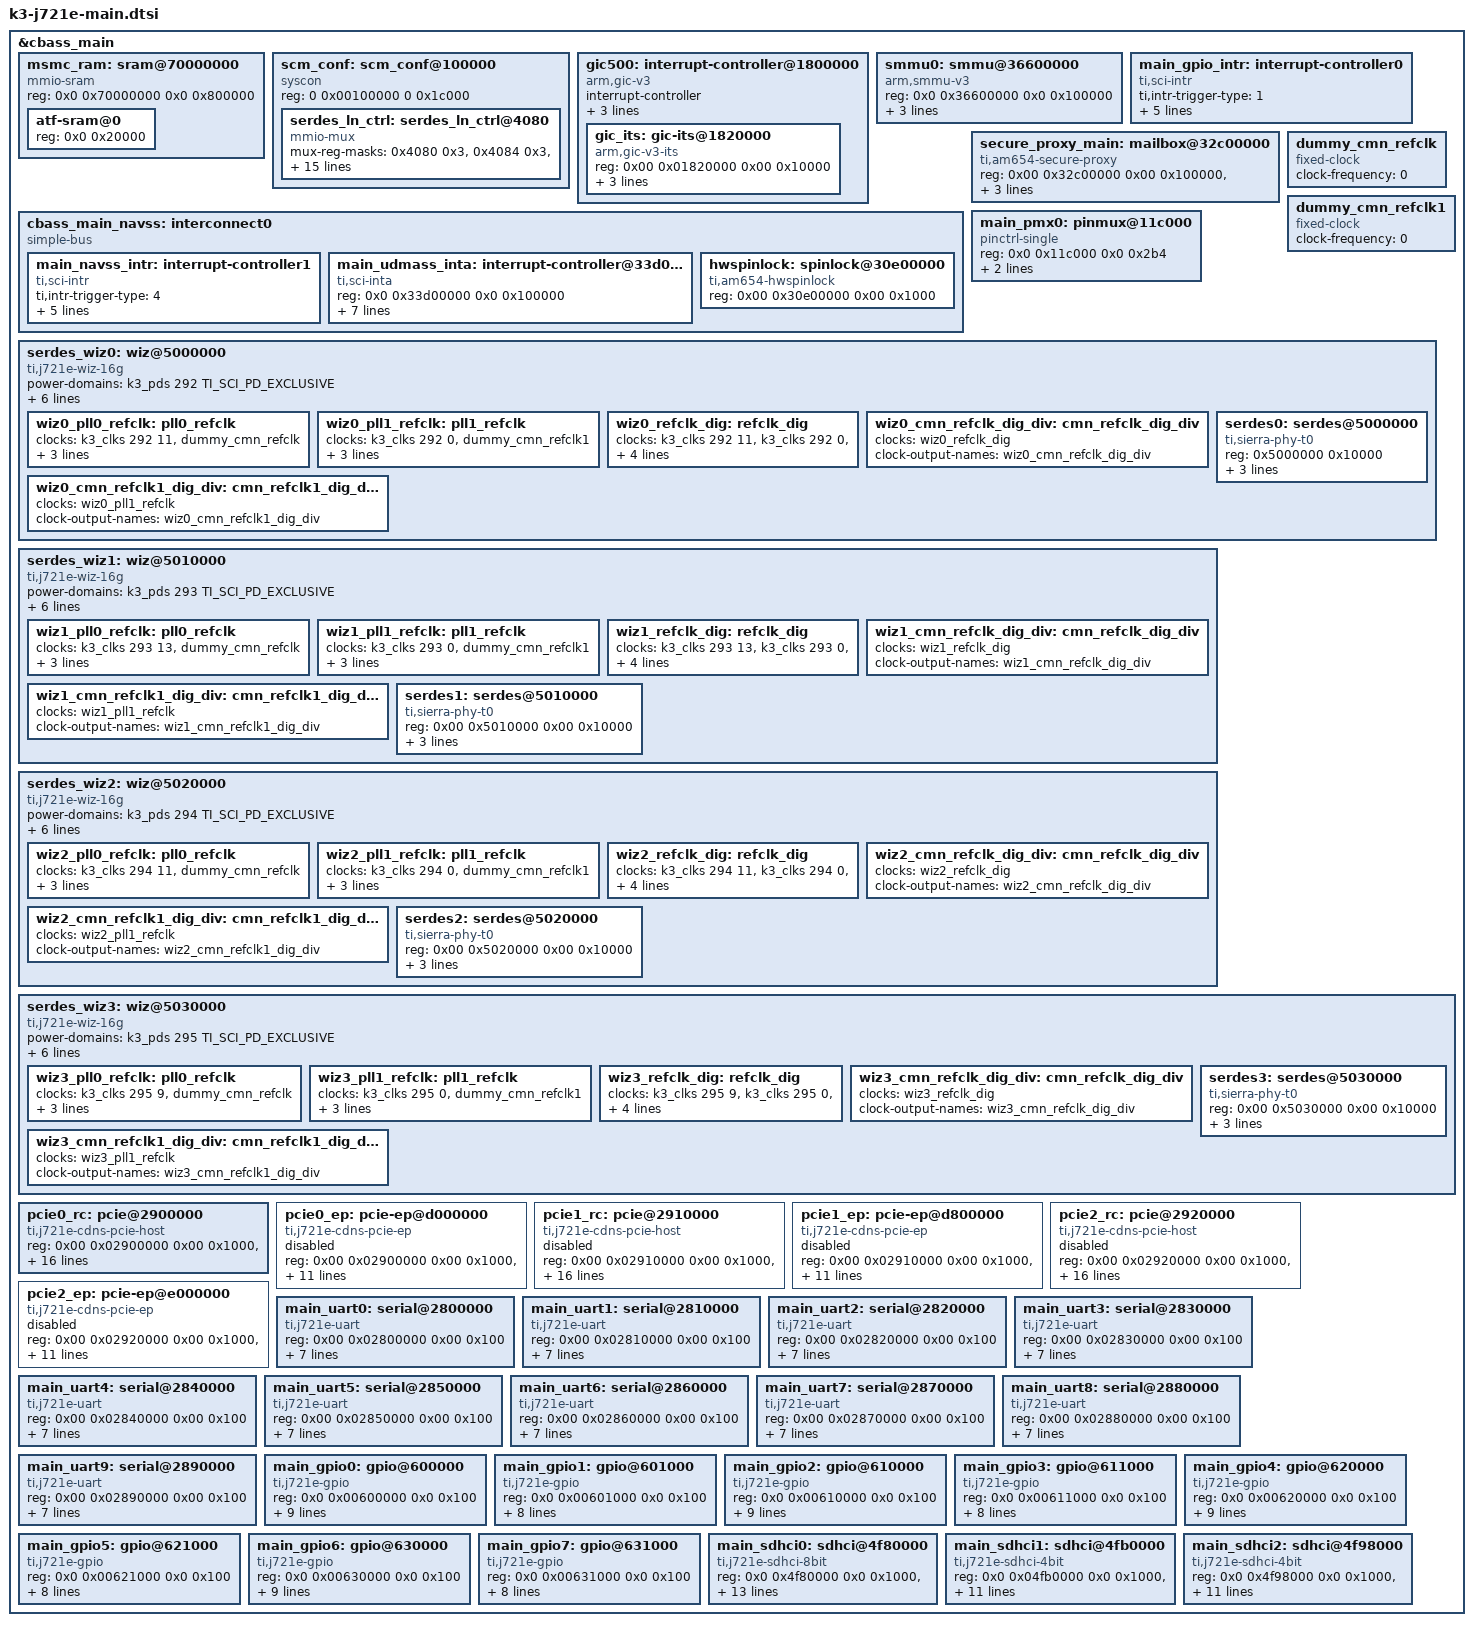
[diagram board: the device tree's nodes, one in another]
// SPDX-License-Identifier: GPL-2.0
/*
 * Device Tree Source for J721E SoC Family Main Domain peripherals
 *
 * Copyright (C) 2016-2019 Texas Instruments Incorporated - http://www.ti.com/
 */
#include <dt-bindings/phy/phy.h>
#include <dt-bindings/mux/mux.h>
#include <dt-bindings/mux/mux-j721e-wiz.h>

&cbass_main {
	msmc_ram: sram@70000000 {
		compatible = "mmio-sram";
		reg = <0x0 0x70000000 0x0 0x800000>;
		#address-cells = <1>;
		#size-cells = <1>;
		ranges = <0x0 0x0 0x70000000 0x800000>;

		atf-sram@0 {
			reg = <0x0 0x20000>;
		};
	};

	scm_conf: scm_conf@100000 {
		compatible = "syscon", "simple-mfd";
		reg = <0 0x00100000 0 0x1c000>;
		#address-cells = <1>;
		#size-cells = <1>;
		ranges = <0x0 0x0 0x00100000 0x1c000>;

		serdes_ln_ctrl: serdes_ln_ctrl@4080 {
			compatible = "mmio-mux";
			#mux-control-cells = <1>;
			mux-reg-masks = <0x4080 0x3>, <0x4084 0x3>, /* SERDES0 lane0/1 select */
					<0x4090 0x3>, <0x4094 0x3>, /* SERDES1 lane0/1 select */
					<0x40a0 0x3>, <0x40a4 0x3>, /* SERDES2 lane0/1 select */
					<0x40b0 0x3>, <0x40b4 0x3>, /* SERDES3 lane0/1 select */
					<0x40c0 0x3>, <0x40c4 0x3>, <0x40c8 0x3>, <0x40cc 0x3>;
					/* SERDES4 lane0/1/2/3 select */
			idle-states = <SERDES0_LANE0_PCIE0_LANE0>, <SERDES0_LANE1_PCIE0_LANE1>,
				      <SERDES1_LANE0_PCIE1_LANE0>, <SERDES1_LANE1_PCIE1_LANE1>,
				      <SERDES2_LANE0_PCIE2_LANE0>, <SERDES2_LANE1_PCIE2_LANE1>,
				      <MUX_IDLE_AS_IS>, <SERDES3_LANE1_USB3_0>,
				      <SERDES4_LANE0_EDP_LANE0>, <SERDES4_LANE1_EDP_LANE1>, <SERDES4_LANE2_EDP_LANE2>, <SERDES4_LANE3_EDP_LANE3>;
		};
	};

	gic500: interrupt-controller@1800000 {
		compatible = "arm,gic-v3";
		#address-cells = <2>;
		#size-cells = <2>;
		ranges;
		#interrupt-cells = <3>;
		interrupt-controller;
		reg = <0x00 0x01800000 0x00 0x10000>,	/* GICD */
		      <0x00 0x01900000 0x00 0x100000>;	/* GICR */

		/* vcpumntirq: virtual CPU interface maintenance interrupt */
		interrupts = <GIC_PPI 9 IRQ_TYPE_LEVEL_HIGH>;

		gic_its: gic-its@1820000 {
			compatible = "arm,gic-v3-its";
			reg = <0x00 0x01820000 0x00 0x10000>;
			socionext,synquacer-pre-its = <0x1000000 0x400000>;
			msi-controller;
			#msi-cells = <1>;
		};
	};

	smmu0: smmu@36600000 {
		compatible = "arm,smmu-v3";
		reg = <0x0 0x36600000 0x0 0x100000>;
		interrupt-parent = <&gic500>;
		interrupts = <GIC_SPI 772 IRQ_TYPE_EDGE_RISING>,
			     <GIC_SPI 768 IRQ_TYPE_EDGE_RISING>;
		interrupt-names = "eventq", "gerror";
		#iommu-cells = <1>;
	};

	main_gpio_intr: interrupt-controller0 {
		compatible = "ti,sci-intr";
		ti,intr-trigger-type = <1>;
		interrupt-controller;
		interrupt-parent = <&gic500>;
		#interrupt-cells = <2>;
		ti,sci = <&dmsc>;
		ti,sci-dst-id = <14>;
		ti,sci-rm-range-girq = <0x1>;
	};

	cbass_main_navss: interconnect0 {
		compatible = "simple-bus";
		#address-cells = <2>;
		#size-cells = <2>;
		ranges;

		main_navss_intr: interrupt-controller1 {
			compatible = "ti,sci-intr";
			ti,intr-trigger-type = <4>;
			interrupt-controller;
			interrupt-parent = <&gic500>;
			#interrupt-cells = <2>;
			ti,sci = <&dmsc>;
			ti,sci-dst-id = <14>;
			ti,sci-rm-range-girq = <0>, <2>;
		};

		main_udmass_inta: interrupt-controller@33d00000 {
			compatible = "ti,sci-inta";
			reg = <0x0 0x33d00000 0x0 0x100000>;
			interrupt-controller;
			interrupt-parent = <&main_navss_intr>;
			msi-controller;
			ti,sci = <&dmsc>;
			ti,sci-dev-id = <209>;
			ti,sci-rm-range-vint = <0xa>;
			ti,sci-rm-range-global-event = <0xd>;
		};

		hwspinlock: spinlock@30e00000 {
			compatible = "ti,am654-hwspinlock";
			reg = <0x00 0x30e00000 0x00 0x1000>;
			#hwlock-cells = <1>;
		};
	};

	secure_proxy_main: mailbox@32c00000 {
		compatible = "ti,am654-secure-proxy";
		#mbox-cells = <1>;
		reg-names = "target_data", "rt", "scfg";
		reg = <0x00 0x32c00000 0x00 0x100000>,
		      <0x00 0x32400000 0x00 0x100000>,
		      <0x00 0x32800000 0x00 0x100000>;
		interrupt-names = "rx_011";
		interrupts = <GIC_SPI 37 IRQ_TYPE_LEVEL_HIGH>;
	};

	main_pmx0: pinmux@11c000 {
		compatible = "pinctrl-single";
		/* Proxy 0 addressing */
		reg = <0x0 0x11c000 0x0 0x2b4>;
		#pinctrl-cells = <1>;
		pinctrl-single,register-width = <32>;
		pinctrl-single,function-mask = <0xffffffff>;
	};

	dummy_cmn_refclk: dummy_cmn_refclk {
		#clock-cells = <0>;
		compatible = "fixed-clock";
		clock-frequency = <0>;
	};

	dummy_cmn_refclk1: dummy_cmn_refclk1 {
		#clock-cells = <0>;
		compatible = "fixed-clock";
		clock-frequency = <0>;
	};

	serdes_wiz0: wiz@5000000 {
		compatible = "ti,j721e-wiz-16g";
		#address-cells = <1>;
		#size-cells = <1>;
		power-domains = <&k3_pds 292 TI_SCI_PD_EXCLUSIVE>;
		clocks = <&k3_clks 292 5>, <&k3_clks 292 11>, <&dummy_cmn_refclk>;
		clock-names = "fck", "core_ref_clk", "ext_ref_clk";
		assigned-clocks = <&k3_clks 292 11>, <&k3_clks 292 0>;
		assigned-clock-parents = <&k3_clks 292 15>, <&k3_clks 292 4>;
		num-lanes = <2>;
		#reset-cells = <1>;
		ranges = <0x5000000 0x0 0x5000000 0x10000>;

		wiz0_pll0_refclk: pll0_refclk {
			clocks = <&k3_clks 292 11>, <&dummy_cmn_refclk>;
			clock-output-names = "wiz0_pll0_refclk";
			#clock-cells = <0>;
			assigned-clocks = <&wiz0_pll0_refclk>;
			assigned-clock-parents = <&k3_clks 292 11>;
		};

		wiz0_pll1_refclk: pll1_refclk {
			clocks = <&k3_clks 292 0>, <&dummy_cmn_refclk1>;
			clock-output-names = "wiz0_pll1_refclk";
			#clock-cells = <0>;
			assigned-clocks = <&wiz0_pll1_refclk>;
			assigned-clock-parents = <&k3_clks 292 0>;
		};

		wiz0_refclk_dig: refclk_dig {
			clocks = <&k3_clks 292 11>, <&k3_clks 292 0>, <&dummy_cmn_refclk>, <&dummy_cmn_refclk1>;
			clock-output-names = "wiz0_refclk_dig";
			#clock-cells = <0>;
			assigned-clocks = <&wiz0_refclk_dig>;
			assigned-clock-parents = <&k3_clks 292 11>;
		};

		wiz0_cmn_refclk_dig_div: cmn_refclk_dig_div {
			clocks = <&wiz0_refclk_dig>;
			clock-output-names = "wiz0_cmn_refclk_dig_div";
			#clock-cells = <0>;
		};

		wiz0_cmn_refclk1_dig_div: cmn_refclk1_dig_div {
			clocks = <&wiz0_pll1_refclk>;
			clock-output-names = "wiz0_cmn_refclk1_dig_div";
			#clock-cells = <0>;
		};

		serdes0: serdes@5000000 {
			compatible = "ti,sierra-phy-t0";
			reg-names = "serdes";
			reg = <0x5000000 0x10000>;
			#address-cells = <1>;
			#size-cells = <0>;
			resets = <&serdes_wiz0 0>;
			reset-names = "sierra_reset";
			clocks = <&wiz0_cmn_refclk_dig_div>, <&wiz0_cmn_refclk1_dig_div>;
			clock-names = "cmn_refclk_dig_div", "cmn_refclk1_dig_div";
		};
	};

	serdes_wiz1: wiz@5010000 {
		compatible = "ti,j721e-wiz-16g";
		#address-cells = <2>;
		#size-cells = <2>;
		power-domains = <&k3_pds 293 TI_SCI_PD_EXCLUSIVE>;
		clocks = <&k3_clks 293 5>, <&k3_clks 293 13>, <&dummy_cmn_refclk>;
		clock-names = "fck", "core_ref_clk", "ext_ref_clk";
		assigned-clocks = <&k3_clks 293 13>, <&k3_clks 293 0>;
		assigned-clock-parents = <&k3_clks 293 17>, <&k3_clks 293 4>;
		num-lanes = <2>;
		#reset-cells = <1>;
		ranges;

		wiz1_pll0_refclk: pll0_refclk {
			clocks = <&k3_clks 293 13>, <&dummy_cmn_refclk>;
			clock-output-names = "wiz1_pll0_refclk";
			#clock-cells = <0>;
			assigned-clocks = <&wiz1_pll0_refclk>;
			assigned-clock-parents = <&k3_clks 293 13>;
		};

		wiz1_pll1_refclk: pll1_refclk {
			clocks = <&k3_clks 293 0>, <&dummy_cmn_refclk1>;
			clock-output-names = "wiz1_pll1_refclk";
			#clock-cells = <0>;
			assigned-clocks = <&wiz1_pll1_refclk>;
			assigned-clock-parents = <&k3_clks 293 0>;
		};

		wiz1_refclk_dig: refclk_dig {
			clocks = <&k3_clks 293 13>, <&k3_clks 293 0>, <&dummy_cmn_refclk>, <&dummy_cmn_refclk1>;
			clock-output-names = "wiz1_refclk_dig";
			#clock-cells = <0>;
			assigned-clocks = <&wiz1_refclk_dig>;
			assigned-clock-parents = <&k3_clks 293 13>;
		};

		wiz1_cmn_refclk_dig_div: cmn_refclk_dig_div{
			clocks = <&wiz1_refclk_dig>;
			clock-output-names = "wiz1_cmn_refclk_dig_div";
			#clock-cells = <0>;
		};

		wiz1_cmn_refclk1_dig_div: cmn_refclk1_dig_div {
			clocks = <&wiz1_pll1_refclk>;
			clock-output-names = "wiz1_cmn_refclk1_dig_div";
			#clock-cells = <0>;
		};

		serdes1: serdes@5010000 {
			compatible = "ti,sierra-phy-t0";
			reg-names = "serdes";
			reg = <0x00 0x5010000 0x00 0x10000>;
			#address-cells = <1>;
			#size-cells = <0>;
			resets = <&serdes_wiz1 0>;
			reset-names = "sierra_reset";
			clocks = <&wiz1_cmn_refclk_dig_div>, <&wiz1_cmn_refclk1_dig_div>;
			clock-names = "cmn_refclk_dig_div", "cmn_refclk1_dig_div";
		};
	};

	serdes_wiz2: wiz@5020000 {
		compatible = "ti,j721e-wiz-16g";
		#address-cells = <2>;
		#size-cells = <2>;
		power-domains = <&k3_pds 294 TI_SCI_PD_EXCLUSIVE>;
		clocks = <&k3_clks 294 5>, <&k3_clks 294 11>, <&dummy_cmn_refclk>;
		clock-names = "fck", "core_ref_clk", "ext_ref_clk";
		assigned-clocks = <&k3_clks 294 11>, <&k3_clks 294 0>;
		assigned-clock-parents = <&k3_clks 294 15>, <&k3_clks 294 4>;
		num-lanes = <2>;
		#reset-cells = <1>;
		ranges;

		wiz2_pll0_refclk: pll0_refclk {
			clocks = <&k3_clks 294 11>, <&dummy_cmn_refclk>;
			clock-output-names = "wiz2_pll0_refclk";
			#clock-cells = <0>;
			assigned-clocks = <&wiz2_pll0_refclk>;
			assigned-clock-parents = <&k3_clks 294 11>;
		};

		wiz2_pll1_refclk: pll1_refclk {
			clocks = <&k3_clks 294 0>, <&dummy_cmn_refclk1>;
			clock-output-names = "wiz2_pll1_refclk";
			#clock-cells = <0>;
			assigned-clocks = <&wiz2_pll1_refclk>;
			assigned-clock-parents = <&k3_clks 294 0>;
		};

		wiz2_refclk_dig: refclk_dig {
			clocks = <&k3_clks 294 11>, <&k3_clks 294 0>, <&dummy_cmn_refclk>, <&dummy_cmn_refclk1>;
			clock-output-names = "wiz2_refclk_dig";
			#clock-cells = <0>;
			assigned-clocks = <&wiz2_refclk_dig>;
			assigned-clock-parents = <&k3_clks 294 11>;
		};

		wiz2_cmn_refclk_dig_div: cmn_refclk_dig_div {
			clocks = <&wiz2_refclk_dig>;
			clock-output-names = "wiz2_cmn_refclk_dig_div";
			#clock-cells = <0>;
		};

		wiz2_cmn_refclk1_dig_div: cmn_refclk1_dig_div {
			clocks = <&wiz2_pll1_refclk>;
			clock-output-names = "wiz2_cmn_refclk1_dig_div";
			#clock-cells = <0>;
		};

		serdes2: serdes@5020000 {
			compatible = "ti,sierra-phy-t0";
			reg-names = "serdes";
			reg = <0x00 0x5020000 0x00 0x10000>;
			#address-cells = <1>;
			#size-cells = <0>;
			resets = <&serdes_wiz2 0>;
			reset-names = "sierra_reset";
			clocks = <&wiz2_cmn_refclk_dig_div>, <&wiz2_cmn_refclk1_dig_div>;
			clock-names = "cmn_refclk_dig_div", "cmn_refclk1_dig_div";
		};
	};

	serdes_wiz3: wiz@5030000 {
		compatible = "ti,j721e-wiz-16g";
		#address-cells = <2>;
		#size-cells = <2>;
		power-domains = <&k3_pds 295 TI_SCI_PD_EXCLUSIVE>;
		clocks = <&k3_clks 295 5>, <&k3_clks 295 9>, <&dummy_cmn_refclk>;
		clock-names = "fck", "core_ref_clk", "ext_ref_clk";
		assigned-clocks = <&k3_clks 295 9>, <&k3_clks 295 0>;
		assigned-clock-parents = <&k3_clks 295 13>, <&k3_clks 295 4>;
		num-lanes = <2>;
		#reset-cells = <1>;
		ranges;

		wiz3_pll0_refclk: pll0_refclk {
			clocks = <&k3_clks 295 9>, <&dummy_cmn_refclk>;
			clock-output-names = "wiz3_pll0_refclk";
			#clock-cells = <0>;
			assigned-clocks = <&wiz3_pll0_refclk>;
			assigned-clock-parents = <&k3_clks 295 9>;
		};

		wiz3_pll1_refclk: pll1_refclk {
			clocks = <&k3_clks 295 0>, <&dummy_cmn_refclk1>;
			clock-output-names = "wiz3_pll1_refclk";
			#clock-cells = <0>;
			assigned-clocks = <&wiz3_pll1_refclk>;
			assigned-clock-parents = <&k3_clks 295 0>;
		};

		wiz3_refclk_dig: refclk_dig {
			clocks = <&k3_clks 295 9>, <&k3_clks 295 0>, <&dummy_cmn_refclk>, <&dummy_cmn_refclk1>;
			clock-output-names = "wiz3_refclk_dig";
			#clock-cells = <0>;
			assigned-clocks = <&wiz3_refclk_dig>;
			assigned-clock-parents = <&k3_clks 295 9>;
		};

		wiz3_cmn_refclk_dig_div: cmn_refclk_dig_div {
			clocks = <&wiz3_refclk_dig>;
			clock-output-names = "wiz3_cmn_refclk_dig_div";
			#clock-cells = <0>;
		};

		wiz3_cmn_refclk1_dig_div: cmn_refclk1_dig_div {
			clocks = <&wiz3_pll1_refclk>;
			clock-output-names = "wiz3_cmn_refclk1_dig_div";
			#clock-cells = <0>;
		};

		serdes3: serdes@5030000 {
			compatible = "ti,sierra-phy-t0";
			reg-names = "serdes";
			reg = <0x00 0x5030000 0x00 0x10000>;
			#address-cells = <1>;
			#size-cells = <0>;
			resets = <&serdes_wiz3 0>;
			reset-names = "sierra_reset";
			clocks = <&wiz3_cmn_refclk_dig_div>, <&wiz3_cmn_refclk1_dig_div>;
			clock-names = "cmn_refclk_dig_div", "cmn_refclk1_dig_div";
		};
	};

	pcie0_rc: pcie@2900000 {
		compatible = "ti,j721e-cdns-pcie-host";
		reg = <0x00 0x02900000 0x00 0x1000>,
		      <0x00 0x02907000 0x00 0x400>,
		      <0x00 0x0d000000 0x00 0x00800000>,
		      <0x00 0x10000000 0x00 0x00001000>;
		reg-names = "intd_cfg", "user_cfg", "reg", "cfg";
		ti,syscon-pcie-ctrl = <&pcie0_ctrl>;
		max-link-speed = <3>;
		num-lanes = <2>;
		power-domains = <&k3_pds 239 TI_SCI_PD_EXCLUSIVE>;
		clocks = <&k3_clks 239 1>;
		clock-names = "fck";
		#address-cells = <3>;
		#size-cells = <2>;
		bus-range = <0x0 0xf>;
		cdns,max-outbound-regions = <16>;
		cdns,no-bar-match-nbits = <32>;
		vendor-id = /bits/ 16 <0x104c>;
		device-id = /bits/ 16 <0xb00d>;
		msi-map = <0x0 &gic_its 0x0 0x10000>;
		iommu-map = <0x0 &smmu0 0x0 0x1000>;
		dma-coherent;
		ranges = <0x01000000 0x0 0x10001000  0x00 0x10001000  0x0 0x0010000>,
			 <0x02000000 0x0 0x10011000  0x00 0x10011000  0x0 0x7fef000>;
	};

	pcie0_ep: pcie-ep@d000000 {
		compatible = "ti,j721e-cdns-pcie-ep";
		reg = <0x00 0x02900000 0x00 0x1000>,
		      <0x00 0x02907000 0x00 0x400>,
		      <0x00 0x0d000000 0x00 0x00800000>,
		      <0x00 0x10000000 0x00 0x08000000>;
		reg-names = "intd_cfg", "user_cfg", "reg", "addr_space";
		ti,syscon-pcie-ctrl = <&pcie0_ctrl>;
		max-link-speed = <3>;
		num-lanes = <2>;
		power-domains = <&k3_pds 239 TI_SCI_PD_EXCLUSIVE>;
		clocks = <&k3_clks 239 1>;
		clock-names = "fck";
		cdns,max-outbound-regions = <16>;
		max-functions = /bits/ 8 <2>;
		dma-coherent;
		status = "disabled";
	};

	pcie1_rc: pcie@2910000 {
		compatible = "ti,j721e-cdns-pcie-host";
		reg = <0x00 0x02910000 0x00 0x1000>,
		      <0x00 0x02917000 0x00 0x400>,
		      <0x00 0x0d800000 0x00 0x00800000>,
		      <0x00 0x18000000 0x00 0x00001000>;
		reg-names = "intd_cfg", "user_cfg", "reg", "cfg";
		ti,syscon-pcie-ctrl = <&pcie1_ctrl>;
		max-link-speed = <3>;
		num-lanes = <2>;
		power-domains = <&k3_pds 240 TI_SCI_PD_EXCLUSIVE>;
		clocks = <&k3_clks 240 1>;
		clock-names = "fck";
		#address-cells = <3>;
		#size-cells = <2>;
		bus-range = <0x0 0xf>;
		cdns,max-outbound-regions = <16>;
		cdns,no-bar-match-nbits = <32>;
		vendor-id = /bits/ 16 <0x104c>;
		device-id = /bits/ 16 <0xb00d>;
		msi-map = <0x0 &gic_its 0x10000 0x10000>;
		iommu-map = <0x0 &smmu0 0x04000 0x1000>;
		dma-coherent;
		ranges = <0x01000000 0x0 0x18001000  0x00 0x18001000  0x0 0x0010000>,
			 <0x02000000 0x0 0x18011000  0x00 0x18011000  0x0 0x7fef000>;
		status = "disabled";
	};

	pcie1_ep: pcie-ep@d800000 {
		compatible = "ti,j721e-cdns-pcie-ep";
		reg = <0x00 0x02910000 0x00 0x1000>,
		      <0x00 0x02917000 0x00 0x400>,
		      <0x00 0x0d800000 0x00 0x00800000>,
		      <0x00 0x18000000 0x00 0x08000000>;
		reg-names = "intd_cfg", "user_cfg", "reg", "addr_space";
		ti,syscon-pcie-ctrl = <&pcie1_ctrl>;
		max-link-speed = <3>;
		num-lanes = <2>;
		power-domains = <&k3_pds 240 TI_SCI_PD_EXCLUSIVE>;
		clocks = <&k3_clks 240 1>;
		clock-names = "fck";
		cdns,max-outbound-regions = <16>;
		max-functions = /bits/ 8 <2>;
		dma-coherent;
		status = "disabled";
	};

	pcie2_rc: pcie@2920000 {
		compatible = "ti,j721e-cdns-pcie-host";
		reg = <0x00 0x02920000 0x00 0x1000>,
		      <0x00 0x02927000 0x00 0x400>,
		      <0x00 0x0e000000 0x00 0x00800000>,
		      <0x44 0x00000000 0x00 0x00001000>;
		reg-names = "intd_cfg", "user_cfg", "reg", "cfg";
		ti,syscon-pcie-ctrl = <&pcie2_ctrl>;
		max-link-speed = <3>;
		num-lanes = <2>;
		power-domains = <&k3_pds 241 TI_SCI_PD_EXCLUSIVE>;
		clocks = <&k3_clks 241 1>;
		clock-names = "fck";
		#address-cells = <3>;
		#size-cells = <2>;
		bus-range = <0x0 0xf>;
		cdns,max-outbound-regions = <16>;
		cdns,no-bar-match-nbits = <32>;
		vendor-id = /bits/ 16 <0x104c>;
		device-id = /bits/ 16 <0xb00d>;
		msi-map = <0x0 &gic_its 0x10000 0x10000>;
		iommu-map = <0x0 &smmu0 0x08000 0x1000>;
		dma-coherent;
		ranges = <0x01000000 0x00 0x00001000  0x44 0x00001000  0x0 0x0010000>,
			 <0x02000000 0x00 0x00011000  0x44 0x00011000  0x0 0x7fef000>;
		status = "disabled";
	};

	pcie2_ep: pcie-ep@e000000 {
		compatible = "ti,j721e-cdns-pcie-ep";
		reg = <0x00 0x02920000 0x00 0x1000>,
		      <0x00 0x02927000 0x00 0x400>,
		      <0x00 0x0e000000 0x00 0x00800000>,
		      <0x44 0x00000000 0x00 0x08000000>;
		reg-names = "intd_cfg", "user_cfg", "reg", "addr_space";
		ti,syscon-pcie-ctrl = <&pcie2_ctrl>;
		max-link-speed = <3>;
		num-lanes = <2>;
		power-domains = <&k3_pds 241 TI_SCI_PD_EXCLUSIVE>;
		clocks = <&k3_clks 241 1>;
		clock-names = "fck";
		cdns,max-outbound-regions = <16>;
		max-functions = /bits/ 8 <2>;
		dma-coherent;
		status = "disabled";
	};

	main_uart0: serial@2800000 {
		compatible = "ti,j721e-uart", "ti,am654-uart";
		reg = <0x00 0x02800000 0x00 0x100>;
		reg-shift = <2>;
		reg-io-width = <4>;
		interrupts = <GIC_SPI 192 IRQ_TYPE_LEVEL_HIGH>;
		clock-frequency = <48000000>;
		current-speed = <115200>;
		power-domains = <&k3_pds 146 TI_SCI_PD_EXCLUSIVE>;
		clocks = <&k3_clks 146 0>;
		clock-names = "fclk";
	};

	main_uart1: serial@2810000 {
		compatible = "ti,j721e-uart", "ti,am654-uart";
		reg = <0x00 0x02810000 0x00 0x100>;
		reg-shift = <2>;
		reg-io-width = <4>;
		interrupts = <GIC_SPI 193 IRQ_TYPE_LEVEL_HIGH>;
		clock-frequency = <48000000>;
		current-speed = <115200>;
		power-domains = <&k3_pds 278 TI_SCI_PD_EXCLUSIVE>;
		clocks = <&k3_clks 278 0>;
		clock-names = "fclk";
	};

	main_uart2: serial@2820000 {
		compatible = "ti,j721e-uart", "ti,am654-uart";
		reg = <0x00 0x02820000 0x00 0x100>;
		reg-shift = <2>;
		reg-io-width = <4>;
		interrupts = <GIC_SPI 194 IRQ_TYPE_LEVEL_HIGH>;
		clock-frequency = <48000000>;
		current-speed = <115200>;
		power-domains = <&k3_pds 279 TI_SCI_PD_EXCLUSIVE>;
		clocks = <&k3_clks 279 0>;
		clock-names = "fclk";
	};

	main_uart3: serial@2830000 {
		compatible = "ti,j721e-uart", "ti,am654-uart";
		reg = <0x00 0x02830000 0x00 0x100>;
		reg-shift = <2>;
		reg-io-width = <4>;
		interrupts = <GIC_SPI 195 IRQ_TYPE_LEVEL_HIGH>;
		clock-frequency = <48000000>;
		current-speed = <115200>;
		power-domains = <&k3_pds 280 TI_SCI_PD_EXCLUSIVE>;
		clocks = <&k3_clks 280 0>;
		clock-names = "fclk";
	};

	main_uart4: serial@2840000 {
		compatible = "ti,j721e-uart", "ti,am654-uart";
		reg = <0x00 0x02840000 0x00 0x100>;
		reg-shift = <2>;
		reg-io-width = <4>;
		interrupts = <GIC_SPI 196 IRQ_TYPE_LEVEL_HIGH>;
		clock-frequency = <48000000>;
		current-speed = <115200>;
		power-domains = <&k3_pds 281 TI_SCI_PD_EXCLUSIVE>;
		clocks = <&k3_clks 281 0>;
		clock-names = "fclk";
	};

	main_uart5: serial@2850000 {
		compatible = "ti,j721e-uart", "ti,am654-uart";
		reg = <0x00 0x02850000 0x00 0x100>;
		reg-shift = <2>;
		reg-io-width = <4>;
		interrupts = <GIC_SPI 197 IRQ_TYPE_LEVEL_HIGH>;
		clock-frequency = <48000000>;
		current-speed = <115200>;
		power-domains = <&k3_pds 282 TI_SCI_PD_EXCLUSIVE>;
		clocks = <&k3_clks 282 0>;
		clock-names = "fclk";
	};

	main_uart6: serial@2860000 {
		compatible = "ti,j721e-uart", "ti,am654-uart";
		reg = <0x00 0x02860000 0x00 0x100>;
		reg-shift = <2>;
		reg-io-width = <4>;
		interrupts = <GIC_SPI 198 IRQ_TYPE_LEVEL_HIGH>;
		clock-frequency = <48000000>;
		current-speed = <115200>;
		power-domains = <&k3_pds 283 TI_SCI_PD_EXCLUSIVE>;
		clocks = <&k3_clks 283 0>;
		clock-names = "fclk";
	};

	main_uart7: serial@2870000 {
		compatible = "ti,j721e-uart", "ti,am654-uart";
		reg = <0x00 0x02870000 0x00 0x100>;
		reg-shift = <2>;
		reg-io-width = <4>;
		interrupts = <GIC_SPI 199 IRQ_TYPE_LEVEL_HIGH>;
		clock-frequency = <48000000>;
		current-speed = <115200>;
		power-domains = <&k3_pds 284 TI_SCI_PD_EXCLUSIVE>;
		clocks = <&k3_clks 284 0>;
		clock-names = "fclk";
	};

	main_uart8: serial@2880000 {
		compatible = "ti,j721e-uart", "ti,am654-uart";
		reg = <0x00 0x02880000 0x00 0x100>;
		reg-shift = <2>;
		reg-io-width = <4>;
		interrupts = <GIC_SPI 248 IRQ_TYPE_LEVEL_HIGH>;
		clock-frequency = <48000000>;
		current-speed = <115200>;
		power-domains = <&k3_pds 285 TI_SCI_PD_EXCLUSIVE>;
		clocks = <&k3_clks 285 0>;
		clock-names = "fclk";
	};

	main_uart9: serial@2890000 {
		compatible = "ti,j721e-uart", "ti,am654-uart";
		reg = <0x00 0x02890000 0x00 0x100>;
		reg-shift = <2>;
		reg-io-width = <4>;
		interrupts = <GIC_SPI 249 IRQ_TYPE_LEVEL_HIGH>;
		clock-frequency = <48000000>;
		current-speed = <115200>;
		power-domains = <&k3_pds 286 TI_SCI_PD_EXCLUSIVE>;
		clocks = <&k3_clks 286 0>;
		clock-names = "fclk";
	};

	main_gpio0: gpio@600000 {
		compatible = "ti,j721e-gpio", "ti,keystone-gpio";
		reg = <0x0 0x00600000 0x0 0x100>;
		gpio-controller;
		#gpio-cells = <2>;
		interrupt-parent = <&main_gpio_intr>;
		interrupts = <105 0>, <105 1>, <105 2>, <105 3>,
			     <105 4>, <105 5>, <105 6>, <105 7>;
		interrupt-controller;
		#interrupt-cells = <2>;
		ti,ngpio = <128>;
		ti,davinci-gpio-unbanked = <0>;
		power-domains = <&k3_pds 105 TI_SCI_PD_EXCLUSIVE>;
		clocks = <&k3_clks 105 0>;
		clock-names = "gpio";
	};

	main_gpio1: gpio@601000 {
		compatible = "ti,j721e-gpio", "ti,keystone-gpio";
		reg = <0x0 0x00601000 0x0 0x100>;
		gpio-controller;
		#gpio-cells = <2>;
		interrupt-parent = <&main_gpio_intr>;
		interrupts = <106 0>, <106 1>, <106 2>;
		interrupt-controller;
		#interrupt-cells = <2>;
		ti,ngpio = <36>;
		ti,davinci-gpio-unbanked = <0>;
		power-domains = <&k3_pds 106 TI_SCI_PD_EXCLUSIVE>;
		clocks = <&k3_clks 106 0>;
		clock-names = "gpio";
	};

	main_gpio2: gpio@610000 {
		compatible = "ti,j721e-gpio", "ti,keystone-gpio";
		reg = <0x0 0x00610000 0x0 0x100>;
		gpio-controller;
		#gpio-cells = <2>;
		interrupt-parent = <&main_gpio_intr>;
		interrupts = <107 0>, <107 1>, <107 2>, <107 3>,
			     <107 4>, <107 5>, <107 6>, <107 7>;
		interrupt-controller;
		#interrupt-cells = <2>;
		ti,ngpio = <128>;
		ti,davinci-gpio-unbanked = <0>;
		power-domains = <&k3_pds 107 TI_SCI_PD_EXCLUSIVE>;
		clocks = <&k3_clks 107 0>;
		clock-names = "gpio";
	};

	main_gpio3: gpio@611000 {
		compatible = "ti,j721e-gpio", "ti,keystone-gpio";
		reg = <0x0 0x00611000 0x0 0x100>;
		gpio-controller;
		#gpio-cells = <2>;
		interrupt-parent = <&main_gpio_intr>;
		interrupts = <108 0>, <108 1>, <108 2>;
		interrupt-controller;
		#interrupt-cells = <2>;
		ti,ngpio = <36>;
		ti,davinci-gpio-unbanked = <0>;
		power-domains = <&k3_pds 108 TI_SCI_PD_EXCLUSIVE>;
		clocks = <&k3_clks 108 0>;
		clock-names = "gpio";
	};

	main_gpio4: gpio@620000 {
		compatible = "ti,j721e-gpio", "ti,keystone-gpio";
		reg = <0x0 0x00620000 0x0 0x100>;
		gpio-controller;
		#gpio-cells = <2>;
		interrupt-parent = <&main_gpio_intr>;
		interrupts = <109 0>, <109 1>, <109 2>, <109 3>,
			     <109 4>, <109 5>, <109 6>, <109 7>;
		interrupt-controller;
		#interrupt-cells = <2>;
		ti,ngpio = <128>;
		ti,davinci-gpio-unbanked = <0>;
		power-domains = <&k3_pds 109 TI_SCI_PD_EXCLUSIVE>;
		clocks = <&k3_clks 109 0>;
		clock-names = "gpio";
	};

	main_gpio5: gpio@621000 {
		compatible = "ti,j721e-gpio", "ti,keystone-gpio";
		reg = <0x0 0x00621000 0x0 0x100>;
		gpio-controller;
		#gpio-cells = <2>;
		interrupt-parent = <&main_gpio_intr>;
		interrupts = <110 0>, <110 1>, <110 2>;
		interrupt-controller;
		#interrupt-cells = <2>;
		ti,ngpio = <36>;
		ti,davinci-gpio-unbanked = <0>;
		power-domains = <&k3_pds 110 TI_SCI_PD_EXCLUSIVE>;
		clocks = <&k3_clks 110 0>;
		clock-names = "gpio";
	};

	main_gpio6: gpio@630000 {
		compatible = "ti,j721e-gpio", "ti,keystone-gpio";
		reg = <0x0 0x00630000 0x0 0x100>;
		gpio-controller;
		#gpio-cells = <2>;
		interrupt-parent = <&main_gpio_intr>;
		interrupts = <111 0>, <111 1>, <111 2>, <111 3>,
			     <111 4>, <111 5>, <111 6>, <111 7>;
		interrupt-controller;
		#interrupt-cells = <2>;
		ti,ngpio = <128>;
		ti,davinci-gpio-unbanked = <0>;
		power-domains = <&k3_pds 111 TI_SCI_PD_EXCLUSIVE>;
		clocks = <&k3_clks 111 0>;
		clock-names = "gpio";
	};

	main_gpio7: gpio@631000 {
		compatible = "ti,j721e-gpio", "ti,keystone-gpio";
		reg = <0x0 0x00631000 0x0 0x100>;
		gpio-controller;
		#gpio-cells = <2>;
		interrupt-parent = <&main_gpio_intr>;
		interrupts = <112 0>, <112 1>, <112 2>;
		interrupt-controller;
		#interrupt-cells = <2>;
		ti,ngpio = <36>;
		ti,davinci-gpio-unbanked = <0>;
		power-domains = <&k3_pds 112 TI_SCI_PD_EXCLUSIVE>;
		clocks = <&k3_clks 112 0>;
		clock-names = "gpio";
	};

	main_sdhci0: sdhci@4f80000 {
		compatible = "ti,j721e-sdhci-8bit";
		reg = <0x0 0x4f80000 0x0 0x1000>, <0x0 0x4f88000 0x0 0x400>;
		interrupts = <GIC_SPI 3 IRQ_TYPE_LEVEL_HIGH>;
		power-domains = <&k3_pds 91 TI_SCI_PD_EXCLUSIVE>;
		clock-names = "clk_xin", "clk_ahb";
		clocks = <&k3_clks 91 1>, <&k3_clks 91 0>;
		assigned-clocks = <&k3_clks 91 1>;
		assigned-clock-parents = <&k3_clks 91 2>;
		bus-width = <8>;
		mmc-hs400-1_8v;
		mmc-ddr-1_8v;
		ti,otap-del-sel = <0x2>;
		ti,trm-icp = <0x8>;
		ti,strobe-sel = <0x77>;
		dma-coherent;
	};

	main_sdhci1: sdhci@4fb0000 {
		compatible = "ti,j721e-sdhci-4bit";
		reg = <0x0 0x04fb0000 0x0 0x1000>, <0x0 0x4fb8000 0x0 0x400>;
		interrupts = <GIC_SPI 4 IRQ_TYPE_LEVEL_HIGH>;
		power-domains = <&k3_pds 92 TI_SCI_PD_EXCLUSIVE>;
		clock-names = "clk_xin", "clk_ahb";
		clocks = <&k3_clks 92 0>, <&k3_clks 92 5>;
		assigned-clocks = <&k3_clks 92 0>;
		assigned-clock-parents = <&k3_clks 92 1>;
		ti,otap-del-sel = <0x2>;
		ti,trm-icp = <0x8>;
		ti,clkbuf-sel = <0x7>;
		dma-coherent;
		no-1-8-v;
	};

	main_sdhci2: sdhci@4f98000 {
		compatible = "ti,j721e-sdhci-4bit";
		reg = <0x0 0x4f98000 0x0 0x1000>, <0x0 0x4f90000 0x0 0x400>;
		interrupts = <GIC_SPI 5 IRQ_TYPE_LEVEL_HIGH>;
		power-domains = <&k3_pds 93 TI_SCI_PD_EXCLUSIVE>;
		clock-names = "clk_xin", "clk_ahb";
		clocks = <&k3_clks 93 0>, <&k3_clks 93 5>;
		assigned-clocks = <&k3_clks 93 0>;
		assigned-clock-parents = <&k3_clks 93 1>;
		ti,otap-del-sel = <0x2>;
		ti,trm-icp = <0x8>;
		ti,clkbuf-sel = <0x7>;
		dma-coherent;
		no-1-8-v;
	};
};
